# PY32F040xx register map
Vendor: Puya; Series: PY32F0; File version: 1.0.0
CPU: CM0+ r0p1, little endian, no MPU, no FPU, 4 interrupt priority bits
Registers are 32-bit, read-write, reset 0x0 unless marked. A register's access mark holds for its fields unless they carry their own. Offsets are from the block's base; [hi:lo] are bit positions.

## OPA — des OPA
Base 0x40010300
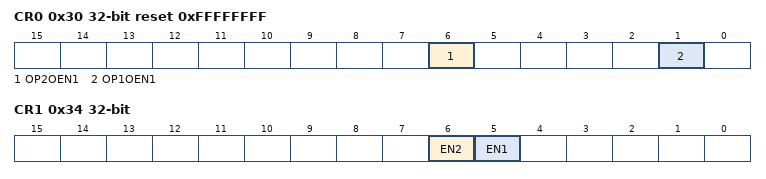
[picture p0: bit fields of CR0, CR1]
0x30 CR0 reset 0xFFFFFFFF
  [6] OP2OEN1, [1] OP1OEN1
0x34 CR1
  [6] EN2, [5] EN1

## PWR — Power control
Base 0x40007000
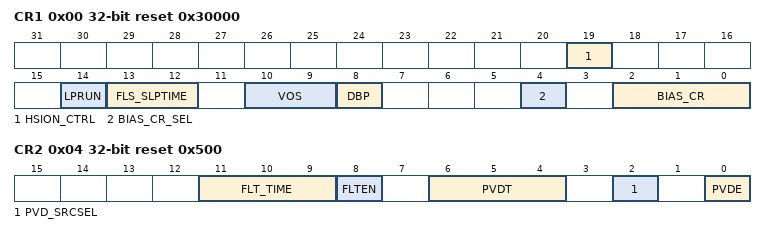
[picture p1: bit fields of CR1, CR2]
0x00 CR1 reset 0x30000 — Power control register 1
  [19] HSION_CTRL — HSI open time control
    0=WaiteMR (Enable HSI after MR is stable); 1=WakeOnVR (Enable HSI when VR is on (enable HSI immediately when wakeup))
  [14] LPRUN — Low-power run
    0=MainMode (Voltage regulator in Main mode in Low-power run mode); 1=LowPowerMode (Voltage regulator in low-power mode in Low-power run mode)
  [13:12] FLS_SLPTIME — Flash wait time after wakeup from the stop mode
  [10:9] VOS — Voltage scaling range selection
    0=V1_2 (1.2 V (range 1)); 1=V1_0 (1.0 V (range 2))
  [8] DBP — Disable backup domain write protection
    0=Disabled (Access to RTC, RTC Backup and RCC CSR registers disabled); 1=Enabled (Access to RTC, RTC Backup and RCC CSR registers enabled)
  [4] BIAS_CR_SEL — MR Bias current selection
    0=FactoryConfig (Bias config from factory config bytes); 1=BiasCR (Bias config from BIAS_CR register)
  [2:0] BIAS_CR range 0..15 — MR Bias current
0x04 CR2 reset 0x500 — Power control register 2
  [11:9] FLT_TIME — Digital filter time configuration
    0=T30us (Filter time is about 30 us); 1=T60us (Filter time is about 60 us); 2=T120us (Filter time is about 120 us); 3=T480us (Filter time is about 480 us); 4=T1_92ms (Filter time is about 1.92 ms); 5=T3_8ms (Filter time is about 3.8 ms); 6=T30_7ms (Filter time is about 30.7 ms)
  [8] FLTEN — Digital filter enable
    0=Disabled (Digital filter disabled); 1=Enabled (Digital filter enabled)
  [6:4] PVDT — Power voltage detector threshold selection
    0=V1_8 (1.8 V); 1=V2_0 (2.0 V); 2=V2_2 (2.2 V); 3=V2_4 (2.4 V); 4=V2_6 (2.6 V); 5=V2_8 (2.8 V); 6=V3_0 (3.0 V); 7=V3_2 (3.2 V)
  [2] PVD_SRCSEL — Power voltage detector volatage selection
    0=Vcc (VCC as detector source); 1=PB7 (PB7 pin as detector source)
  [0] PVDE — Power voltage detector enable
    0=Disabled (PVD Disabled); 1=Enabled (PVD Enabled)
0x14 SR ro — Power status register
  [11] PVDO — PVD output
    0=AboveThreshold (VDD is higher than the PVD threshold selected with the PLS[2:0] bits); 1=BelowThreshold (VDD is lower than the PVD threshold selected with the PLS[2:0] bits)

## RTC
Base 0x40002800
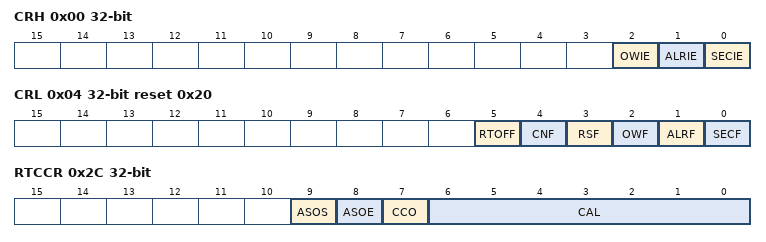
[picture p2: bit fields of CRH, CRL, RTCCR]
0x00 CRH
  [2] OWIE
    0=Disabled (Overflow interrupt is masked); 1=Enabled (Overflow interrupt is enabled)
  [1] ALRIE
    0=Disabled (Alarm interrupt is masked); 1=Enabled (Alarm interrupt is enabled)
  [0] SECIE
    0=Disabled (Second interrupt is masked); 1=Enabled (Second interrupt is enabled)
0x04 CRL reset 0x20
  [5] RTOFF ro
    0=Enabled (Last write operation on RTC registers is still ongoing); 1=Disabled (Last write operation on RTC registers terminated)
  [4] CNF
    0=Exit configuration mode (start update of RTC registers); 1=Enter configuration mode
  [3] RSF write-0-clears
    on read: 0=NotSynchronized (Registers not yet synchronized); 1=Synchronized (Registers synchronized) | on write: 0=Clear flag
  [2] OWF write-0-clears
    on read: 0=NoOverflow (Overflow not detected); 1=Overflow (32-bit programmable counter overflow occurred) | on write: 0=Clear flag
  [1] ALRF write-0-clears
    on read: 0=NoAlarm (Alarm not detected); 1=Alarm detected | on write: 0=Clear flag
  [0] SECF write-0-clears
    on read: 0=NoPrescalerOverflow (Second flag condition not met); 1=PrescalerOverflow (Second flag condition met) | on write: 0=Clear flag
0x08 PRLH wo
  [3:0] PRLH — desc PRL
0x0C PRLL wo reset 0x8000
  [15:0] PRLL — desc PRL
0x10 DIVH ro
  [3:0] DIVH — desc DIV
0x14 DIVL ro reset 0x8000
  [15:0] DIVL — desc DIV
0x18 CNTH
  [15:0] CNTH — desc RTC_CNT
0x1C CNTL
  [15:0] CNTL — desc RTC_CNT
0x20 ALRH reset 0xFFFF
  [15:0] ALRH — desc RTC_ALR
0x24 ALRL reset 0xFFFF
  [15:0] ALRL — desc RTC_ALR
0x2C RTCCR — desc BKP_RTCCR
  [9] ASOS
    0=Alarm (RTC Alarm pulse output selected); 1=Second (RTC Second pulse output selected)
  [8] ASOE
    0=Disabled; 1=Enabled (Setting this bit outputs either the RTC Alarm pulse signal or the Second pulse signal on the TAMPER pin depending on the ASOS bit)
  [7] CCO
    0=Disabled (Calibration clock output disabled); 1=Enabled (Setting this bit output calibration clock (RTC clock / 64) on the pin)
  [6:0] CAL range 0..121

## WWDG — Window watchdog
Base 0x40002C00
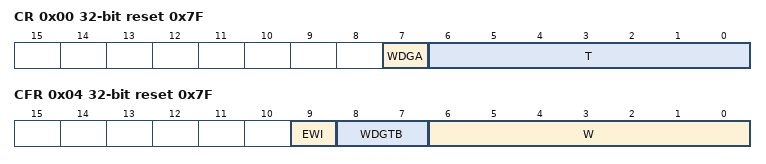
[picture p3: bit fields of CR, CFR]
0x00 CR reset 0x7F — Control register (WWDG_CR)
  [7] WDGA — Activation bit
    0=Disabled (Watchdog disabled); 1=Enabled (Watchdog enabled)
  [6:0] T — 7-bit counter (MSB to LSB)
0x04 CFR reset 0x7F — Configuration register (WWDG_CFR)
  [9] EWI — Early Wakeup Interrupt
    on write: 1=Enable (interrupt occurs whenever the counter reaches the value 0x40)
  [8:7] WDGTB — Timer Base
    0=Div1 (Counter clock (PCLK1 div 4096) div 1); 1=Div2 (Counter clock (PCLK1 div 4096) div 2); 2=Div4 (Counter clock (PCLK1 div 4096) div 4); 3=Div8 (Counter clock (PCLK1 div 4096) div 8)
  [6:0] W — 7-bit window value
0x08 SR — Status register (WWDG_SR)
  [0] EWIF write-0-clears — Early Wakeup Interrupt flag
    on read: 0=Finished (The EWI Interrupt Service Routine has been serviced); 1=Pending (The EWI Interrupt Service Routine has been triggered) | on write: 0=Finished (The EWI Interrupt Service Routine has been serviced)
